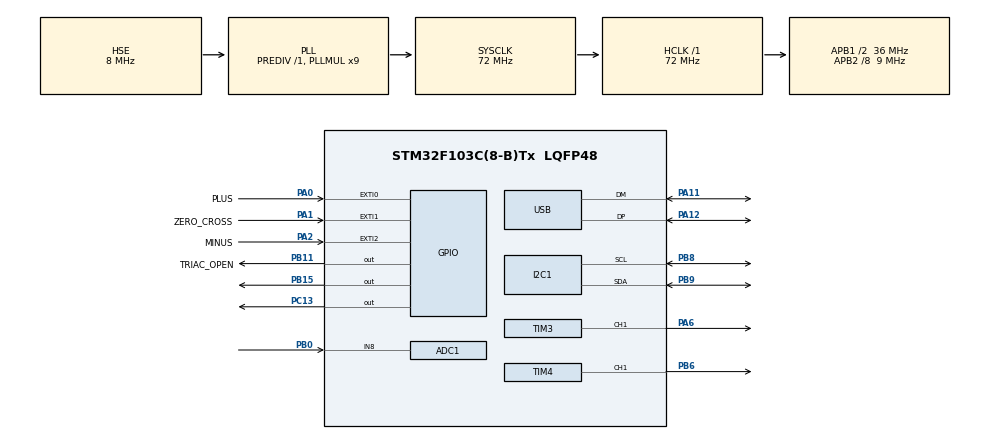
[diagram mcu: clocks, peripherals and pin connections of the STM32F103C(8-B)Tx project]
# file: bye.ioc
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ADC1.Channel-0\#ChannelRegularConversion=ADC_CHANNEL_8
ADC1.NbrOfConversionFlag=1
ADC1.Rank-0\#ChannelRegularConversion=1
ADC1.SamplingTime-0\#ChannelRegularConversion=ADC_SAMPLETIME_1CYCLE_5
ADC1.master=1
Mcu.Family=STM32F1
Mcu.Name=STM32F103C(8-B)Tx
Mcu.Package=LQFP48
NVIC.ADC1_2_IRQn=true\:0\:0\:false\:false\:true\:true
NVIC.EXTI1_IRQn=true\:0\:0\:false\:false\:true\:true
NVIC.PriorityGroup=NVIC_PRIORITYGROUP_4
NVIC.TIM4_IRQn=true\:0\:0\:false\:false\:true\:true
NVIC.USB_LP_CAN1_RX0_IRQn=true\:0\:0\:false\:false\:true\:false
PA0-WKUP.GPIO_Label=PLUS
PA0-WKUP.GPIO_ModeDefaultEXTI=GPIO_MODE_IT_FALLING
PA0-WKUP.GPIO_PuPd=GPIO_PULLUP
PA0-WKUP.Signal=GPXTI0
PA1.GPIO_Label=ZERO_CROSS
PA1.GPIO_ModeDefaultEXTI=GPIO_MODE_IT_RISING
PA1.GPIO_PuPd=GPIO_PULLDOWN
PA1.Signal=GPXTI1
PA11.Mode=Device
PA11.Signal=USB_DM
PA12.Mode=Device
PA12.Signal=USB_DP
PA13.Mode=Serial_Wire
PA13.Signal=SYS_JTMS-SWDIO
PA14.Mode=Serial_Wire
PA14.Signal=SYS_JTCK-SWCLK
PA2.GPIO_Label=MINUS
PA2.GPIO_ModeDefaultEXTI=GPIO_MODE_IT_FALLING
PA2.GPIO_PuPd=GPIO_PULLUP
PA2.Signal=GPXTI2
PA6.Signal=S_TIM3_CH1
PB0.Signal=ADCx_IN8
PB11.GPIO_Label=TRIAC_OPEN
PB11.GPIO_ModeDefaultOutputPP=GPIO_MODE_OUTPUT_PP
PB11.GPIO_Speed=GPIO_SPEED_FREQ_MEDIUM
PB11.Signal=GPIO_Output
PB15.GPIO_Speed=GPIO_SPEED_FREQ_MEDIUM
PB15.Signal=GPIO_Output
PB6.Signal=S_TIM4_CH1
PB8.Mode=I2C
PB8.Signal=I2C1_SCL
PB9.Mode=I2C
PB9.Signal=I2C1_SDA
PC13-TAMPER-RTC.GPIO_Speed=GPIO_SPEED_FREQ_MEDIUM
PC13-TAMPER-RTC.Signal=GPIO_Output
PD0-OSC_IN.Mode=HSE-External-Oscillator
PD0-OSC_IN.Signal=RCC_OSC_IN
PD1-OSC_OUT.Mode=HSE-External-Oscillator
PD1-OSC_OUT.Signal=RCC_OSC_OUT
ProjectManager.HeapSize=0x200
ProjectManager.StackSize=0x400
ProjectManager.TargetToolchain=MDK-ARM V5
RCC.AHBFreq_Value=72000000
RCC.APB1CLKDivider=RCC_HCLK_DIV2
RCC.APB1Freq_Value=36000000
RCC.APB1TimFreq_Value=72000000
RCC.APB2CLKDivider=RCC_HCLK_DIV8
RCC.APB2Freq_Value=9000000
RCC.APB2TimFreq_Value=18000000
RCC.HCLKFreq_Value=72000000
RCC.PLLMUL=RCC_PLL_MUL9
RCC.PLLSourceVirtual=RCC_PLLSOURCE_HSE
RCC.SYSCLKFreq_VALUE=72000000
RCC.SYSCLKSource=RCC_SYSCLKSOURCE_PLLCLK
RCC.USBFreq_Value=48000000
RCC.USBPrescaler=RCC_USBCLKSOURCE_PLL_DIV1_5
SH.ADCx_IN8.0=ADC1_IN8,IN8
SH.S_TIM3_CH1.0=TIM3_CH1,Output Compare1 CH1
SH.S_TIM4_CH1.0=TIM4_CH1,Output Compare1 CH1
TIM3.Channel-Output\ Compare1\ CH1=TIM_CHANNEL_1
TIM3.Period=1000
TIM3.Prescaler=41999
TIM4.Channel-Output\ Compare1\ CH1=TIM_CHANNEL_1
TIM4.Period=1000
TIM4.Prescaler=30000
USB_DEVICE.CLASS_NAME_FS=CUSTOMHID
USB_DEVICE.MANUFACTURER_STRING=STMicroelectronics
USB_DEVICE.PRODUCT_STRING_CUSTOMHID_FS=STM32 Custom Human interface
USB_DEVICE.USBD_CUSTOM_HID_REPORT_DESC_SIZE=108
USB_DEVICE.VirtualMode=CustomHid
USB_DEVICE.VirtualModeFS=Custom_Hid_FS
VP_USB_DEVICE_VS_USB_DEVICE_CUSTOM_HID_FS.Mode=CUSTOM_HID_FS
board=bye

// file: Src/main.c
/**
  ******************************************************************************
  * File Name          : main.c
  * Description        : Main program body
  ******************************************************************************
  * This notice applies to any and all portions of this file
  * that are not between comment pairs USER CODE BEGIN and
  * USER CODE END. Other portions of this file, whether
  * inserted by the user or by software development tools
  * are owned by their respective copyright owners.
  *
  * Copyright (c) 2018 STMicroelectronics International N.V.
  * All rights reserved.
  *
  * Redistribution and use in source and binary forms, with or without
  * modification, are permitted, provided that the following conditions are met:
  *
  * 1. Redistribution of source code must retain the above copyright notice,
  *    this list of conditions and the following disclaimer.
  * 2. Redistributions in binary form must reproduce the above copyright notice,
  *    this list of conditions and the following disclaimer in the documentation
  *    and/or other materials provided with the distribution.
  * 3. Neither the name of STMicroelectronics nor the names of other
  *    contributors to this software may be used to endorse or promote products
  *    derived from this software without specific written permission.
  * 4. This software, including modifications and/or derivative works of this
  *    software, must execute solely and exclusively on microcontroller or
  *    microprocessor devices manufactured by or for STMicroelectronics.
  * 5. Redistribution and use of this software other than as permitted under
  *    this license is void and will automatically terminate your rights under
  *    this license.
  *
  * THIS SOFTWARE IS PROVIDED BY STMICROELECTRONICS AND CONTRIBUTORS "AS IS"
  * AND ANY EXPRESS, IMPLIED OR STATUTORY WARRANTIES, INCLUDING, BUT NOT
  * LIMITED TO, THE IMPLIED WARRANTIES OF MERCHANTABILITY, FITNESS FOR A
  * PARTICULAR PURPOSE AND NON-INFRINGEMENT OF THIRD PARTY INTELLECTUAL PROPERTY
  * RIGHTS ARE DISCLAIMED TO THE FULLEST EXTENT PERMITTED BY LAW. IN NO EVENT
  * SHALL STMICROELECTRONICS OR CONTRIBUTORS BE LIABLE FOR ANY DIRECT, INDIRECT,
  * INCIDENTAL, SPECIAL, EXEMPLARY, OR CONSEQUENTIAL DAMAGES (INCLUDING, BUT NOT
  * LIMITED TO, PROCUREMENT OF SUBSTITUTE GOODS OR SERVICES; LOSS OF USE, DATA,
  * OR PROFITS; OR BUSINESS INTERRUPTION) HOWEVER CAUSED AND ON ANY THEORY OF
  * LIABILITY, WHETHER IN CONTRACT, STRICT LIABILITY, OR TORT (INCLUDING
  * NEGLIGENCE OR OTHERWISE) ARISING IN ANY WAY OUT OF THE USE OF THIS SOFTWARE,
  * EVEN IF ADVISED OF THE POSSIBILITY OF SUCH DAMAGE.
  *
  ******************************************************************************
  */

#include "main.h"
#include "stm32f1xx_hal.h"
#include "usb_device.h"

/* USER CODE BEGIN Includes */
#include "triac.c"
#include "variable.h"
#include "lcd.c"
//#include "adc.c"
#include "stdio.h"
#include "usbd_customhid.h"
#include "usb.c"

/* USER CODE END Includes */

ADC_HandleTypeDef hadc1;

I2C_HandleTypeDef hi2c1;

TIM_HandleTypeDef htim3;
TIM_HandleTypeDef htim4;

/* USER CODE BEGIN PV */
/* Private variables ---------------------------------------------------------*/

/* USER CODE END PV */

void SystemClock_Config(void);
static void MX_GPIO_Init(void);
static void MX_TIM4_Init(void);
static void MX_I2C1_Init(void);
static void MX_ADC1_Init(void);
static void MX_TIM3_Init(void);

void HAL_TIM_MspPostInit(TIM_HandleTypeDef *htim);

/* USER CODE BEGIN PFP */
/* Private function prototypes -----------------------------------------------*/

/* USER CODE END PFP */

int main(void)
{

  /* MCU Configuration----------------------------------------------------------*/

  /* Reset of all peripherals, Initializes the Flash interface and the Systick. */
  HAL_Init();

  /* Configure the system clock */
  SystemClock_Config();

  /* Initialize all configured peripherals */
  MX_GPIO_Init();
  MX_TIM4_Init();
  MX_I2C1_Init();
  MX_ADC1_Init();
  MX_USB_DEVICE_Init();
  MX_TIM3_Init();

  /* USER CODE BEGIN 2 */

  HAL_GPIO_WritePin(GPIOC, GPIO_PIN_13, GPIO_PIN_SET);
  HAL_GPIO_WritePin(GPIOB, GPIO_PIN_11, GPIO_PIN_RESET);
  //HAL_TIM_Base_Start(&htim4);
  //HAL_TIM_Base_Start_IT(&htim4);

  HAL_Delay(100);
   OLED_init();
   LCD_Clear();
	 //HAL_Delay(2000);
		HAL_NVIC_EnableIRQ(EXTI1_IRQn);
  /* USER CODE END 2 */

  /* Infinite loop */
  while (1)
  {

  /* USER CODE BEGIN 3 */
	 HAL_TIM_PeriodElapsedCallback(&htim3);

   OLED_OUTPUT();

  }
  /* USER CODE END 3 */

}

/** System Clock Configuration
*/
void SystemClock_Config(void)
{

  RCC_OscInitTypeDef RCC_OscInitStruct;
  RCC_ClkInitTypeDef RCC_ClkInitStruct;
  RCC_PeriphCLKInitTypeDef PeriphClkInit;

    /**Initializes the CPU, AHB and APB busses clocks
    */
  RCC_OscInitStruct.OscillatorType = RCC_OSCILLATORTYPE_HSE;
  RCC_OscInitStruct.HSEState = RCC_HSE_ON;
  RCC_OscInitStruct.HSEPredivValue = RCC_HSE_PREDIV_DIV1;
  RCC_OscInitStruct.HSIState = RCC_HSI_ON;
  RCC_OscInitStruct.PLL.PLLState = RCC_PLL_ON;
  RCC_OscInitStruct.PLL.PLLSource = RCC_PLLSOURCE_HSE;
  RCC_OscInitStruct.PLL.PLLMUL = RCC_PLL_MUL9;
  if (HAL_RCC_OscConfig(&RCC_OscInitStruct) != HAL_OK)
  {
    _Error_Handler(__FILE__, __LINE__);
  }

    /**Initializes the CPU, AHB and APB busses clocks
    */
  RCC_ClkInitStruct.ClockType = RCC_CLOCKTYPE_HCLK|RCC_CLOCKTYPE_SYSCLK
                              |RCC_CLOCKTYPE_PCLK1|RCC_CLOCKTYPE_PCLK2;
  RCC_ClkInitStruct.SYSCLKSource = RCC_SYSCLKSOURCE_PLLCLK;
  RCC_ClkInitStruct.AHBCLKDivider = RCC_SYSCLK_DIV1;
  RCC_ClkInitStruct.APB1CLKDivider = RCC_HCLK_DIV2;
  RCC_ClkInitStruct.APB2CLKDivider = RCC_HCLK_DIV8;

  if (HAL_RCC_ClockConfig(&RCC_ClkInitStruct, FLASH_LATENCY_2) != HAL_OK)
  {
    _Error_Handler(__FILE__, __LINE__);
  }

  PeriphClkInit.PeriphClockSelection = RCC_PERIPHCLK_ADC|RCC_PERIPHCLK_USB;
  PeriphClkInit.AdcClockSelection = RCC_ADCPCLK2_DIV2;
  PeriphClkInit.UsbClockSelection = RCC_USBCLKSOURCE_PLL_DIV1_5;
  if (HAL_RCCEx_PeriphCLKConfig(&PeriphClkInit) != HAL_OK)
  {
    _Error_Handler(__FILE__, __LINE__);
  }

    /**Configure the Systick interrupt time
    */
  HAL_SYSTICK_Config(HAL_RCC_GetHCLKFreq()/1000);

    /**Configure the Systick
    */
  HAL_SYSTICK_CLKSourceConfig(SYSTICK_CLKSOURCE_HCLK);

  /* SysTick_IRQn interrupt configuration */
  HAL_NVIC_SetPriority(SysTick_IRQn, 0, 0);
}

/* ADC1 init function */
static void MX_ADC1_Init(void)
{

  ADC_ChannelConfTypeDef sConfig;

    /**Common config
    */
  hadc1.Instance = ADC1;
  hadc1.Init.ScanConvMode = ADC_SCAN_DISABLE;
  hadc1.Init.ContinuousConvMode = DISABLE;
  hadc1.Init.DiscontinuousConvMode = DISABLE;
  hadc1.Init.ExternalTrigConv = ADC_SOFTWARE_START;
  hadc1.Init.DataAlign = ADC_DATAALIGN_RIGHT;
  hadc1.Init.NbrOfConversion = 1;
  if (HAL_ADC_Init(&hadc1) != HAL_OK)
  {
    _Error_Handler(__FILE__, __LINE__);
  }

    /**Configure Regular Channel
    */
  sConfig.Channel = ADC_CHANNEL_8;
  sConfig.Rank = 1;
  sConfig.SamplingTime = ADC_SAMPLETIME_1CYCLE_5;
  if (HAL_ADC_ConfigChannel(&hadc1, &sConfig) != HAL_OK)
  {
    _Error_Handler(__FILE__, __LINE__);
  }

}

/* I2C1 init function */
static void MX_I2C1_Init(void)
{

  hi2c1.Instance = I2C1;
  hi2c1.Init.ClockSpeed = 100000;
  hi2c1.Init.DutyCycle = I2C_DUTYCYCLE_2;
  hi2c1.Init.OwnAddress1 = 0;
  hi2c1.Init.AddressingMode = I2C_ADDRESSINGMODE_7BIT;
  hi2c1.Init.DualAddressMode = I2C_DUALADDRESS_DISABLE;
  hi2c1.Init.OwnAddress2 = 0;
  hi2c1.Init.GeneralCallMode = I2C_GENERALCALL_DISABLE;
  hi2c1.Init.NoStretchMode = I2C_NOSTRETCH_DISABLE;
  if (HAL_I2C_Init(&hi2c1) != HAL_OK)
  {
    _Error_Handler(__FILE__, __LINE__);
  }

}

/* TIM3 init function */
static void MX_TIM3_Init(void)
{

  TIM_MasterConfigTypeDef sMasterConfig;
  TIM_OC_InitTypeDef sConfigOC;

  htim3.Instance = TIM3;
  htim3.Init.Prescaler = 41999;
  htim3.Init.CounterMode = TIM_COUNTERMODE_UP;
  htim3.Init.Period = 1000;
  htim3.Init.ClockDivision = TIM_CLOCKDIVISION_DIV1;
  htim3.Init.AutoReloadPreload = TIM_AUTORELOAD_PRELOAD_DISABLE;
  if (HAL_TIM_OC_Init(&htim3) != HAL_OK)
  {
    _Error_Handler(__FILE__, __LINE__);
  }

  sMasterConfig.MasterOutputTrigger = TIM_TRGO_RESET;
  sMasterConfig.MasterSlaveMode = TIM_MASTERSLAVEMODE_DISABLE;
  if (HAL_TIMEx_MasterConfigSynchronization(&htim3, &sMasterConfig) != HAL_OK)
  {
    _Error_Handler(__FILE__, __LINE__);
  }

  sConfigOC.OCMode = TIM_OCMODE_TIMING;
  sConfigOC.Pulse = 0;
  sConfigOC.OCPolarity = TIM_OCPOLARITY_HIGH;
  sConfigOC.OCFastMode = TIM_OCFAST_DISABLE;
  if (HAL_TIM_OC_ConfigChannel(&htim3, &sConfigOC, TIM_CHANNEL_1) != HAL_OK)
  {
    _Error_Handler(__FILE__, __LINE__);
  }

  HAL_TIM_MspPostInit(&htim3);

}

/* TIM4 init function */
static void MX_TIM4_Init(void)
{

  TIM_MasterConfigTypeDef sMasterConfig;
  TIM_OC_InitTypeDef sConfigOC;

  htim4.Instance = TIM4;
  htim4.Init.Prescaler = 30000;
  htim4.Init.CounterMode = TIM_COUNTERMODE_UP;
  htim4.Init.Period = 1000;
  htim4.Init.ClockDivision = TIM_CLOCKDIVISION_DIV1;
  htim4.Init.AutoReloadPreload = TIM_AUTORELOAD_PRELOAD_DISABLE;
  if (HAL_TIM_OC_Init(&htim4) != HAL_OK)
  {
    _Error_Handler(__FILE__, __LINE__);
  }

  sMasterConfig.MasterOutputTrigger = TIM_TRGO_RESET;
  sMasterConfig.MasterSlaveMode = TIM_MASTERSLAVEMODE_DISABLE;
  if (HAL_TIMEx_MasterConfigSynchronization(&htim4, &sMasterConfig) != HAL_OK)
  {
    _Error_Handler(__FILE__, __LINE__);
  }

  sConfigOC.OCMode = TIM_OCMODE_TIMING;
  sConfigOC.Pulse = 0;
  sConfigOC.OCPolarity = TIM_OCPOLARITY_HIGH;
  sConfigOC.OCFastMode = TIM_OCFAST_DISABLE;
  if (HAL_TIM_OC_ConfigChannel(&htim4, &sConfigOC, TIM_CHANNEL_1) != HAL_OK)
  {
    _Error_Handler(__FILE__, __LINE__);
  }

  HAL_TIM_MspPostInit(&htim4);

}

/** Configure pins as
        * Analog
        * Input
        * Output
        * EVENT_OUT
        * EXTI
*/
static void MX_GPIO_Init(void)
{

  GPIO_InitTypeDef GPIO_InitStruct;

  /* GPIO Ports Clock Enable */
  __HAL_RCC_GPIOC_CLK_ENABLE();
  __HAL_RCC_GPIOD_CLK_ENABLE();
  __HAL_RCC_GPIOA_CLK_ENABLE();
  __HAL_RCC_GPIOB_CLK_ENABLE();

  /*Configure GPIO pin Output Level */
  HAL_GPIO_WritePin(GPIOC, GPIO_PIN_13, GPIO_PIN_RESET);

  /*Configure GPIO pin Output Level */
  HAL_GPIO_WritePin(GPIOB, TRIAC_OPEN_Pin|GPIO_PIN_15, GPIO_PIN_RESET);

  /*Configure GPIO pin : PC13 */
  GPIO_InitStruct.Pin = GPIO_PIN_13;
  GPIO_InitStruct.Mode = GPIO_MODE_OUTPUT_PP;
  GPIO_InitStruct.Speed = GPIO_SPEED_FREQ_MEDIUM;
  HAL_GPIO_Init(GPIOC, &GPIO_InitStruct);

  /*Configure GPIO pins : PLUS_Pin MINUS_Pin */
  GPIO_InitStruct.Pin = PLUS_Pin|MINUS_Pin;
  GPIO_InitStruct.Mode = GPIO_MODE_IT_FALLING;
  GPIO_InitStruct.Pull = GPIO_PULLUP;
  HAL_GPIO_Init(GPIOA, &GPIO_InitStruct);

  /*Configure GPIO pin : ZERO_CROSS_Pin */
  GPIO_InitStruct.Pin = ZERO_CROSS_Pin;
  GPIO_InitStruct.Mode = GPIO_MODE_IT_RISING;
  GPIO_InitStruct.Pull = GPIO_PULLDOWN;
  HAL_GPIO_Init(ZERO_CROSS_GPIO_Port, &GPIO_InitStruct);

  /*Configure GPIO pins : TRIAC_OPEN_Pin PB15 */
  GPIO_InitStruct.Pin = TRIAC_OPEN_Pin|GPIO_PIN_15;
  GPIO_InitStruct.Mode = GPIO_MODE_OUTPUT_PP;
  GPIO_InitStruct.Speed = GPIO_SPEED_FREQ_MEDIUM;
  HAL_GPIO_Init(GPIOB, &GPIO_InitStruct);

  /* EXTI interrupt init*/
  HAL_NVIC_SetPriority(EXTI1_IRQn, 0, 0);
  HAL_NVIC_EnableIRQ(EXTI1_IRQn);

}

void _Error_Handler(char * file, int line)
{
  while(1)
  {
  }
}

/************************ (C) COPYRIGHT STMicroelectronics *****END OF FILE****/
